# CTRL_MODULE_CORE_PAD register map
Vendor: Texas Instruments
Registers are 32-bit, access per field, reset 0x10F010F unless marked. A register's access mark holds for its fields unless they carry their own. Offsets are as the file gives them; [hi:lo] are bit positions; 'fields as' and 'values as' point back to an identical list.

## CTRL_MODULE_CORE_PAD (part 4 of 7)
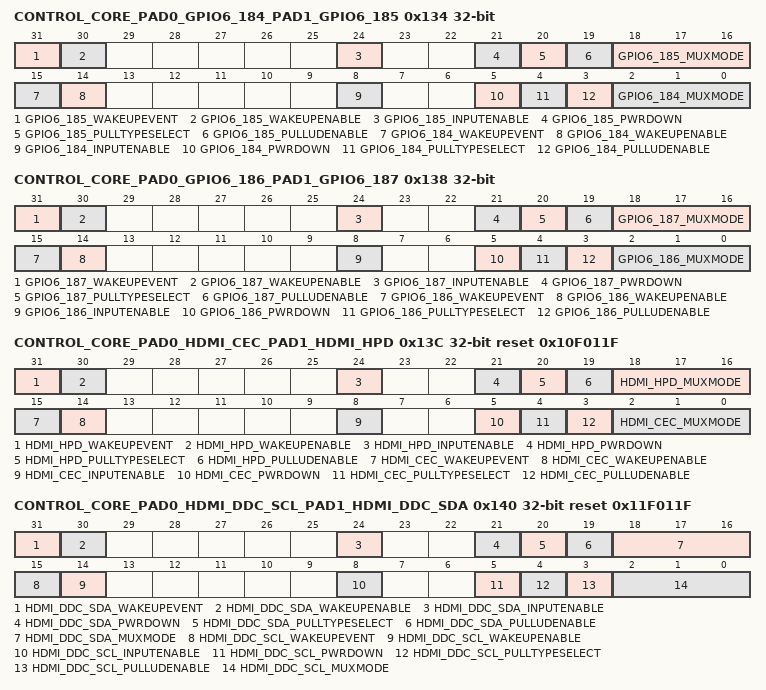
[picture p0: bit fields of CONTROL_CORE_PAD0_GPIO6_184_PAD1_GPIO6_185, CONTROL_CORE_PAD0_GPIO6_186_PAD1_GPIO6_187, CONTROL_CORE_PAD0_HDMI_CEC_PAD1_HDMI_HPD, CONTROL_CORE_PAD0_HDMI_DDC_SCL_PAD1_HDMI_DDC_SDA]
0x134 CONTROL_CORE_PAD0_GPIO6_184_PAD1_GPIO6_185 — Register control for Pads gpio6_184 and gpio6_185 Access conditions. Read: unrestricted, Write: unrestricted
  [31] GPIO6_185_WAKEUPEVENT ro — Pad_x wake-up event status latched in the IO
    1=WakeUp (A wake-up event occurred); 0=No wake-up event occurred
  [30] GPIO6_185_WAKEUPENABLE rw — Input pad wake-up enable
    0=DetectLow (wake-up detection is disabled); 1=DetectLowHigh (wake-up detection is enabled)
  [24] GPIO6_185_INPUTENABLE rw — Input enable value for pad gpio6_185
    0=InputBufferDisabled (Input buffer of IO cell is disabled); 1=InputBufferEnabled (Input buffer of IO cell is enabled)
  [21] GPIO6_185_PWRDOWN rw — Power Down setting for pad gpio6_185
    0=PwrDownDisabled (IO cell power is ON); 1=PwrDownEnabled (IO cell power is OFF)
  [20] GPIO6_185_PULLTYPESELECT rw — Pull-Up/Down selection for pad gpio6_185
    0=Pull-Down selected; 1=Pull-Up selected
  [19] GPIO6_185_PULLUDENABLE rw — Pull-Up/Down enable for pad gpio6_185
    0=PullDisabled (Pull-Up/Down disabled); 1=PullEnabled (Pull-Up/Down enabled)
  [18:16] GPIO6_185_MUXMODE rw — Functional multiplexing selection for pad gpio6_185
    6=SEL_GPIO6_185_1 (Select gpio6_185); 7=SEL_SAFE_MODE_CORE87 (Select safe_mode_core87); 0=SEL_GPIO6_185 (Select gpio6_185); 4=SEL_KBD_ROW0 (Select kbd_row0); 5=SEL_HW_DBG23 (Select hw_dbg23); 3=SEL_DISPC_DATA21 (Select dispc_data21)
  [15] GPIO6_184_WAKEUPEVENT ro — Pad_x wake-up event status latched in the IO
    values as GPIO6_185_WAKEUPEVENT
  [14] GPIO6_184_WAKEUPENABLE rw — Input pad wake-up enable
    values as GPIO6_185_WAKEUPENABLE
  [8] GPIO6_184_INPUTENABLE rw — Input enable value for pad gpio6_184
    values as GPIO6_185_INPUTENABLE
  [5] GPIO6_184_PWRDOWN rw — Power Down setting for pad gpio6_184
    values as GPIO6_185_PWRDOWN
  [4] GPIO6_184_PULLTYPESELECT rw — Pull-Up/Down selection for pad gpio6_184
    0=Pull-Down selected; 1=Pull-Up selected
  [3] GPIO6_184_PULLUDENABLE rw — Pull-Up/Down enable for pad gpio6_184
    values as GPIO6_185_PULLUDENABLE
  [2:0] GPIO6_184_MUXMODE rw — Functional multiplexing selection for pad gpio6_184
    6=SEL_GPIO6_184_1 (Select gpio6_184); 7=SEL_SAFE_MODE_CORE86 (Select safe_mode_core86); 0=SEL_GPIO6_184 (Select gpio6_184); 4=SEL_KBD_COL2 (Select kbd_col2); 5=SEL_HW_DBG22 (Select hw_dbg22); 3=SEL_DISPC_DATA20 (Select dispc_data20)
0x138 CONTROL_CORE_PAD0_GPIO6_186_PAD1_GPIO6_187 — Register control for Pads gpio6_186 and gpio6_187 Access conditions. Read: unrestricted, Write: unrestricted
  [31] GPIO6_187_WAKEUPEVENT ro — Pad_x wake-up event status latched in the IO
    values as CONTROL_CORE_PAD0_GPIO6_184_PAD1_GPIO6_185.GPIO6_185_WAKEUPEVENT
  [30] GPIO6_187_WAKEUPENABLE rw — Input pad wake-up enable
    values as CONTROL_CORE_PAD0_GPIO6_184_PAD1_GPIO6_185.GPIO6_185_WAKEUPENABLE
  [24] GPIO6_187_INPUTENABLE rw — Input enable value for pad gpio6_187
    values as CONTROL_CORE_PAD0_GPIO6_184_PAD1_GPIO6_185.GPIO6_185_INPUTENABLE
  [21] GPIO6_187_PWRDOWN rw — Power Down setting for pad gpio6_187
    values as CONTROL_CORE_PAD0_GPIO6_184_PAD1_GPIO6_185.GPIO6_185_PWRDOWN
  [20] GPIO6_187_PULLTYPESELECT rw — Pull-Up/Down selection for pad gpio6_187
    0=Pull-Down selected; 1=Pull-Up selected
  [19] GPIO6_187_PULLUDENABLE rw — Pull-Up/Down enable for pad gpio6_187
    values as CONTROL_CORE_PAD0_GPIO6_184_PAD1_GPIO6_185.GPIO6_185_PULLUDENABLE
  [18:16] GPIO6_187_MUXMODE rw — Functional multiplexing selection for pad gpio6_187
    6=SEL_GPIO6_187_1 (Select gpio6_187); 7=SEL_SAFE_MODE_CORE89 (Select safe_mode_core89); 0=SEL_GPIO6_187 (Select gpio6_187); 4=SEL_KBD_ROW2 (Select kbd_row2); 5=SEL_HW_DBG25 (Select hw_dbg25); 3=SEL_DISPC_DATA23 (Select dispc_data23)
  [15] GPIO6_186_WAKEUPEVENT ro — Pad_x wake-up event status latched in the IO
    values as CONTROL_CORE_PAD0_GPIO6_184_PAD1_GPIO6_185.GPIO6_185_WAKEUPEVENT
  [14] GPIO6_186_WAKEUPENABLE rw — Input pad wake-up enable
    values as CONTROL_CORE_PAD0_GPIO6_184_PAD1_GPIO6_185.GPIO6_185_WAKEUPENABLE
  [8] GPIO6_186_INPUTENABLE rw — Input enable value for pad gpio6_186
    values as CONTROL_CORE_PAD0_GPIO6_184_PAD1_GPIO6_185.GPIO6_185_INPUTENABLE
  [5] GPIO6_186_PWRDOWN rw — Power Down setting for pad gpio6_186
    values as CONTROL_CORE_PAD0_GPIO6_184_PAD1_GPIO6_185.GPIO6_185_PWRDOWN
  [4] GPIO6_186_PULLTYPESELECT rw — Pull-Up/Down selection for pad gpio6_186
    0=Pull-Down selected; 1=Pull-Up selected
  [3] GPIO6_186_PULLUDENABLE rw — Pull-Up/Down enable for pad gpio6_186
    values as CONTROL_CORE_PAD0_GPIO6_184_PAD1_GPIO6_185.GPIO6_185_PULLUDENABLE
  [2:0] GPIO6_186_MUXMODE rw — Functional multiplexing selection for pad gpio6_186
    6=SEL_GPIO6_186_1 (Select gpio6_186); 7=SEL_SAFE_MODE_CORE88 (Select safe_mode_core88); 0=SEL_GPIO6_186 (Select gpio6_186); 4=SEL_KBD_ROW1 (Select kbd_row1); 5=SEL_HW_DBG24 (Select hw_dbg24); 3=SEL_DISPC_DATA22 (Select dispc_data22)
0x13C CONTROL_CORE_PAD0_HDMI_CEC_PAD1_HDMI_HPD reset 0x10F011F — Register control for Pads hdmi_cec and hdmi_hpd Access conditions. Read: unrestricted, Write: unrestricted
  [31] HDMI_HPD_WAKEUPEVENT ro — Pad_x wake-up event status latched in the IO
    values as CONTROL_CORE_PAD0_GPIO6_184_PAD1_GPIO6_185.GPIO6_185_WAKEUPEVENT
  [30] HDMI_HPD_WAKEUPENABLE rw — Input pad wake-up enable
    values as CONTROL_CORE_PAD0_GPIO6_184_PAD1_GPIO6_185.GPIO6_185_WAKEUPENABLE
  [24] HDMI_HPD_INPUTENABLE rw — Input enable value for pad hdmi_hpd
    values as CONTROL_CORE_PAD0_GPIO6_184_PAD1_GPIO6_185.GPIO6_185_INPUTENABLE
  [21] HDMI_HPD_PWRDOWN rw — Power Down setting for pad hdmi_hpd
    values as CONTROL_CORE_PAD0_GPIO6_184_PAD1_GPIO6_185.GPIO6_185_PWRDOWN
  [20] HDMI_HPD_PULLTYPESELECT rw — Pull-Up/Down selection for pad hdmi_hpd
    0=Pull-Down selected; 1=Pull-Up selected
  [19] HDMI_HPD_PULLUDENABLE rw — Pull-Up/Down enable for pad hdmi_hpd
    values as CONTROL_CORE_PAD0_GPIO6_184_PAD1_GPIO6_185.GPIO6_185_PULLUDENABLE
  [18:16] HDMI_HPD_MUXMODE rw — Functional multiplexing selection for pad hdmi_hpd
    0=SEL_HDMI_HPD (Select hdmi_hpd); 7=SEL_SAFE_MODE_CORE107 (Select safe_mode_core107); 6=SEL_GPIO7_193 (Select gpio7_193)
  [15] HDMI_CEC_WAKEUPEVENT ro — Pad_x wake-up event status latched in the IO
    values as CONTROL_CORE_PAD0_GPIO6_184_PAD1_GPIO6_185.GPIO6_185_WAKEUPEVENT
  [14] HDMI_CEC_WAKEUPENABLE rw — Input pad wake-up enable
    values as CONTROL_CORE_PAD0_GPIO6_184_PAD1_GPIO6_185.GPIO6_185_WAKEUPENABLE
  [8] HDMI_CEC_INPUTENABLE rw — Input enable value for pad hdmi_cec
    values as CONTROL_CORE_PAD0_GPIO6_184_PAD1_GPIO6_185.GPIO6_185_INPUTENABLE
  [5] HDMI_CEC_PWRDOWN rw — Power Down setting for pad hdmi_cec
    values as CONTROL_CORE_PAD0_GPIO6_184_PAD1_GPIO6_185.GPIO6_185_PWRDOWN
  [4] HDMI_CEC_PULLTYPESELECT rw — Pull-Up/Down selection for pad hdmi_cec
    0=Pull-Down selected; 1=Pull-Up selected
  [3] HDMI_CEC_PULLUDENABLE rw — Pull-Up/Down enable for pad hdmi_cec
    values as CONTROL_CORE_PAD0_GPIO6_184_PAD1_GPIO6_185.GPIO6_185_PULLUDENABLE
  [2:0] HDMI_CEC_MUXMODE rw — Functional multiplexing selection for pad hdmi_cec
    0=SEL_HDMI_CEC (Select hdmi_cec); 7=SEL_SAFE_MODE_CORE106 (Select safe_mode_core106); 6=SEL_GPIO7_192 (Select gpio7_192)
0x140 CONTROL_CORE_PAD0_HDMI_DDC_SCL_PAD1_HDMI_DDC_SDA reset 0x11F011F — Register control for Pads hdmi_ddc_scl and hdmi_ddc_sda Access conditions. Read: unrestricted, Write: unrestricted
  [31] HDMI_DDC_SDA_WAKEUPEVENT ro — Pad_x wake-up event status latched in the IO
    values as CONTROL_CORE_PAD0_GPIO6_184_PAD1_GPIO6_185.GPIO6_185_WAKEUPEVENT
  [30] HDMI_DDC_SDA_WAKEUPENABLE rw — Input pad wake-up enable
    values as CONTROL_CORE_PAD0_GPIO6_184_PAD1_GPIO6_185.GPIO6_185_WAKEUPENABLE
  [24] HDMI_DDC_SDA_INPUTENABLE rw — Input enable value for pad hdmi_ddc_sda
    values as CONTROL_CORE_PAD0_GPIO6_184_PAD1_GPIO6_185.GPIO6_185_INPUTENABLE
  [21] HDMI_DDC_SDA_PWRDOWN rw — Power Down setting for pad hdmi_ddc_sda
    values as CONTROL_CORE_PAD0_GPIO6_184_PAD1_GPIO6_185.GPIO6_185_PWRDOWN
  [20] HDMI_DDC_SDA_PULLTYPESELECT rw — Pull-Up/Down selection for pad hdmi_ddc_sda
    0=Pull-Down selected; 1=Pull-Up selected
  [19] HDMI_DDC_SDA_PULLUDENABLE rw — Pull-Up/Down enable for pad hdmi_ddc_sda
    values as CONTROL_CORE_PAD0_GPIO6_184_PAD1_GPIO6_185.GPIO6_185_PULLUDENABLE
  [18:16] HDMI_DDC_SDA_MUXMODE rw — Functional multiplexing selection for pad hdmi_ddc_sda
    0=SEL_HDMI_DDC_SDA (Select hdmi_ddc_sda); 7=SEL_SAFE_MODE_CORE109 (Select safe_mode_core109); 6=SEL_GPIO7_195 (Select gpio7_195)
  [15] HDMI_DDC_SCL_WAKEUPEVENT ro — Pad_x wake-up event status latched in the IO
    values as CONTROL_CORE_PAD0_GPIO6_184_PAD1_GPIO6_185.GPIO6_185_WAKEUPEVENT
  [14] HDMI_DDC_SCL_WAKEUPENABLE rw — Input pad wake-up enable
    values as CONTROL_CORE_PAD0_GPIO6_184_PAD1_GPIO6_185.GPIO6_185_WAKEUPENABLE
  [8] HDMI_DDC_SCL_INPUTENABLE rw — Input enable value for pad hdmi_ddc_scl
    values as CONTROL_CORE_PAD0_GPIO6_184_PAD1_GPIO6_185.GPIO6_185_INPUTENABLE
  [5] HDMI_DDC_SCL_PWRDOWN rw — Power Down setting for pad hdmi_ddc_scl
    values as CONTROL_CORE_PAD0_GPIO6_184_PAD1_GPIO6_185.GPIO6_185_PWRDOWN
  [4] HDMI_DDC_SCL_PULLTYPESELECT rw — Pull-Up/Down selection for pad hdmi_ddc_scl
    0=Pull-Down selected; 1=Pull-Up selected
  [3] HDMI_DDC_SCL_PULLUDENABLE rw — Pull-Up/Down enable for pad hdmi_ddc_scl
    values as CONTROL_CORE_PAD0_GPIO6_184_PAD1_GPIO6_185.GPIO6_185_PULLUDENABLE
  [2:0] HDMI_DDC_SCL_MUXMODE rw — Functional multiplexing selection for pad hdmi_ddc_scl
    0=SEL_HDMI_DDC_SCL (Select hdmi_ddc_scl); 7=SEL_SAFE_MODE_CORE108 (Select safe_mode_core108); 6=SEL_GPIO7_194 (Select gpio7_194)
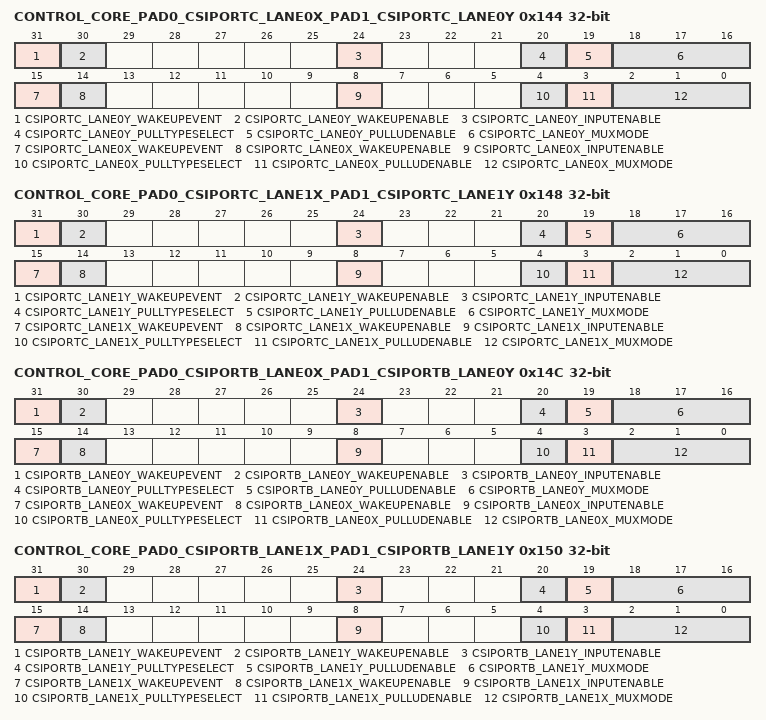
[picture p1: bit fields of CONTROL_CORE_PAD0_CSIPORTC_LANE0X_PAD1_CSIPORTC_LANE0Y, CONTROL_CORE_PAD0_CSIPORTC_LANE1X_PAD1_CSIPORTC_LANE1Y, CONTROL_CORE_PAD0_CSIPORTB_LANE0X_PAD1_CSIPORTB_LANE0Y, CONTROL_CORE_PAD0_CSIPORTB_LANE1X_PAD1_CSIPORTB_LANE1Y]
0x144 CONTROL_CORE_PAD0_CSIPORTC_LANE0X_PAD1_CSIPORTC_LANE0Y — Register control for Pads csiportc_lane0x and csiportc_lane0y Access conditions. Read: unrestricted, Write: unrestricted
  [31] CSIPORTC_LANE0Y_WAKEUPEVENT ro — Pad_x wake-up event status latched in the IO
    values as CONTROL_CORE_PAD0_GPIO6_184_PAD1_GPIO6_185.GPIO6_185_WAKEUPEVENT
  [30] CSIPORTC_LANE0Y_WAKEUPENABLE rw — Input pad wake-up enable
    values as CONTROL_CORE_PAD0_GPIO6_184_PAD1_GPIO6_185.GPIO6_185_WAKEUPENABLE
  [24] CSIPORTC_LANE0Y_INPUTENABLE rw — Input enable value for pad csiportc_lane0y
    values as CONTROL_CORE_PAD0_GPIO6_184_PAD1_GPIO6_185.GPIO6_185_INPUTENABLE
  [20] CSIPORTC_LANE0Y_PULLTYPESELECT rw — Pull-Up/Down selection for pad csiportc_lane0y
    0=Pull-Down selected; 1=Pull-Up selected
  [19] CSIPORTC_LANE0Y_PULLUDENABLE rw — Pull-Up/Down enable for pad csiportc_lane0y
    values as CONTROL_CORE_PAD0_GPIO6_184_PAD1_GPIO6_185.GPIO6_185_PULLUDENABLE
  [18:16] CSIPORTC_LANE0Y_MUXMODE rw — Functional multiplexing selection for pad csiportc_lane0y
    0=SEL_CSIPORTC_LANE0Y (Select csiportc_lane0y); 3=SEL_CPI_DATA8 (Select cpi_data8); 7=SEL_SAFE_MODE_CORE126 (Select safe_mode_core126); 6=SEL_GPIO8_IN252 (Select gpio8_in252)
  [15] CSIPORTC_LANE0X_WAKEUPEVENT ro — Pad_x wake-up event status latched in the IO
    values as CONTROL_CORE_PAD0_GPIO6_184_PAD1_GPIO6_185.GPIO6_185_WAKEUPEVENT
  [14] CSIPORTC_LANE0X_WAKEUPENABLE rw — Input pad wake-up enable
    values as CONTROL_CORE_PAD0_GPIO6_184_PAD1_GPIO6_185.GPIO6_185_WAKEUPENABLE
  [8] CSIPORTC_LANE0X_INPUTENABLE rw — Input enable value for pad csiportc_lane0x
    values as CONTROL_CORE_PAD0_GPIO6_184_PAD1_GPIO6_185.GPIO6_185_INPUTENABLE
  [4] CSIPORTC_LANE0X_PULLTYPESELECT rw — Pull-Up/Down selection for pad csiportc_lane0x
    0=Pull-Down selected; 1=Pull-Up selected
  [3] CSIPORTC_LANE0X_PULLUDENABLE rw — Pull-Up/Down enable for pad csiportc_lane0x
    values as CONTROL_CORE_PAD0_GPIO6_184_PAD1_GPIO6_185.GPIO6_185_PULLUDENABLE
  [2:0] CSIPORTC_LANE0X_MUXMODE rw — Functional multiplexing selection for pad csiportc_lane0x
    0=SEL_CSIPORTC_LANE0X (Select csiportc_lane0x); 3=SEL_CPI_DATA9 (Select cpi_data9); 7=SEL_SAFE_MODE_CORE127 (Select safe_mode_core127); 6=SEL_GPIO8_IN253 (Select gpio8_in253)
0x148 CONTROL_CORE_PAD0_CSIPORTC_LANE1X_PAD1_CSIPORTC_LANE1Y — Register control for Pads csiportc_lane1x and csiportc_lane1y Access conditions. Read: unrestricted, Write: unrestricted
  [31] CSIPORTC_LANE1Y_WAKEUPEVENT ro — Pad_x wake-up event status latched in the IO
    values as CONTROL_CORE_PAD0_GPIO6_184_PAD1_GPIO6_185.GPIO6_185_WAKEUPEVENT
  [30] CSIPORTC_LANE1Y_WAKEUPENABLE rw — Input pad wake-up enable
    values as CONTROL_CORE_PAD0_GPIO6_184_PAD1_GPIO6_185.GPIO6_185_WAKEUPENABLE
  [24] CSIPORTC_LANE1Y_INPUTENABLE rw — Input enable value for pad csiportc_lane1y
    values as CONTROL_CORE_PAD0_GPIO6_184_PAD1_GPIO6_185.GPIO6_185_INPUTENABLE
  [20] CSIPORTC_LANE1Y_PULLTYPESELECT rw — Pull-Up/Down selection for pad csiportc_lane1y
    0=Pull-Down selected; 1=Pull-Up selected
  [19] CSIPORTC_LANE1Y_PULLUDENABLE rw — Pull-Up/Down enable for pad csiportc_lane1y
    values as CONTROL_CORE_PAD0_GPIO6_184_PAD1_GPIO6_185.GPIO6_185_PULLUDENABLE
  [18:16] CSIPORTC_LANE1Y_MUXMODE rw — Functional multiplexing selection for pad csiportc_lane1y
    0=SEL_CSIPORTC_LANE1Y (Select csiportc_lane1y); 3=SEL_CPI_DATA10 (Select cpi_data10); 7=SEL_SAFE_MODE_CORE128 (Select safe_mode_core128); 6=SEL_GPIO8_IN254 (Select gpio8_in254)
  [15] CSIPORTC_LANE1X_WAKEUPEVENT ro — Pad_x wake-up event status latched in the IO
    values as CONTROL_CORE_PAD0_GPIO6_184_PAD1_GPIO6_185.GPIO6_185_WAKEUPEVENT
  [14] CSIPORTC_LANE1X_WAKEUPENABLE rw — Input pad wake-up enable
    values as CONTROL_CORE_PAD0_GPIO6_184_PAD1_GPIO6_185.GPIO6_185_WAKEUPENABLE
  [8] CSIPORTC_LANE1X_INPUTENABLE rw — Input enable value for pad csiportc_lane1x
    values as CONTROL_CORE_PAD0_GPIO6_184_PAD1_GPIO6_185.GPIO6_185_INPUTENABLE
  [4] CSIPORTC_LANE1X_PULLTYPESELECT rw — Pull-Up/Down selection for pad csiportc_lane1x
    0=Pull-Down selected; 1=Pull-Up selected
  [3] CSIPORTC_LANE1X_PULLUDENABLE rw — Pull-Up/Down enable for pad csiportc_lane1x
    values as CONTROL_CORE_PAD0_GPIO6_184_PAD1_GPIO6_185.GPIO6_185_PULLUDENABLE
  [2:0] CSIPORTC_LANE1X_MUXMODE rw — Functional multiplexing selection for pad csiportc_lane1x
    0=SEL_CSIPORTC_LANE1X (Select csiportc_lane1x); 3=SEL_CPI_DATA11 (Select cpi_data11); 7=SEL_SAFE_MODE_CORE129 (Select safe_mode_core129); 6=SEL_GPIO8_IN255 (Select gpio8_in255)
0x14C CONTROL_CORE_PAD0_CSIPORTB_LANE0X_PAD1_CSIPORTB_LANE0Y — Register control for Pads csiportb_lane0x and csiportb_lane0y Access conditions. Read: unrestricted, Write: unrestricted
  [31] CSIPORTB_LANE0Y_WAKEUPEVENT ro — Pad_x wake-up event status latched in the IO
    values as CONTROL_CORE_PAD0_GPIO6_184_PAD1_GPIO6_185.GPIO6_185_WAKEUPEVENT
  [30] CSIPORTB_LANE0Y_WAKEUPENABLE rw — Input pad wake-up enable
    values as CONTROL_CORE_PAD0_GPIO6_184_PAD1_GPIO6_185.GPIO6_185_WAKEUPENABLE
  [24] CSIPORTB_LANE0Y_INPUTENABLE rw — Input enable value for pad csiportb_lane0y
    values as CONTROL_CORE_PAD0_GPIO6_184_PAD1_GPIO6_185.GPIO6_185_INPUTENABLE
  [20] CSIPORTB_LANE0Y_PULLTYPESELECT rw — Pull-Up/Down selection for pad csiportb_lane0y
    0=Pull-Down selected; 1=Pull-Up selected
  [19] CSIPORTB_LANE0Y_PULLUDENABLE rw — Pull-Up/Down enable for pad csiportb_lane0y
    values as CONTROL_CORE_PAD0_GPIO6_184_PAD1_GPIO6_185.GPIO6_185_PULLUDENABLE
  [18:16] CSIPORTB_LANE0Y_MUXMODE rw — Functional multiplexing selection for pad csiportb_lane0y
    0=SEL_CSIPORTB_LANE0Y (Select csiportb_lane0y); 4=SEL_CPI_DATA13 (Select cpi_data13); 7=SEL_SAFE_MODE_CORE121 (Select safe_mode_core121); 6=SEL_GPIO8_IN247 (Select gpio8_in247)
  [15] CSIPORTB_LANE0X_WAKEUPEVENT ro — Pad_x wake-up event status latched in the IO
    values as CONTROL_CORE_PAD0_GPIO6_184_PAD1_GPIO6_185.GPIO6_185_WAKEUPEVENT
  [14] CSIPORTB_LANE0X_WAKEUPENABLE rw — Input pad wake-up enable
    values as CONTROL_CORE_PAD0_GPIO6_184_PAD1_GPIO6_185.GPIO6_185_WAKEUPENABLE
  [8] CSIPORTB_LANE0X_INPUTENABLE rw — Input enable value for pad csiportb_lane0x
    values as CONTROL_CORE_PAD0_GPIO6_184_PAD1_GPIO6_185.GPIO6_185_INPUTENABLE
  [4] CSIPORTB_LANE0X_PULLTYPESELECT rw — Pull-Up/Down selection for pad csiportb_lane0x
    0=Pull-Down selected; 1=Pull-Up selected
  [3] CSIPORTB_LANE0X_PULLUDENABLE rw — Pull-Up/Down enable for pad csiportb_lane0x
    values as CONTROL_CORE_PAD0_GPIO6_184_PAD1_GPIO6_185.GPIO6_185_PULLUDENABLE
  [2:0] CSIPORTB_LANE0X_MUXMODE rw — Functional multiplexing selection for pad csiportb_lane0x
    0=SEL_CSIPORTB_LANE0X (Select csiportb_lane0x); 4=SEL_CPI_DATA12 (Select cpi_data12); 7=SEL_SAFE_MODE_CORE120 (Select safe_mode_core120); 6=SEL_GPIO8_IN246 (Select gpio8_in246)
0x150 CONTROL_CORE_PAD0_CSIPORTB_LANE1X_PAD1_CSIPORTB_LANE1Y — Register control for Pads csiportb_lane1x and csiportb_lane1y Access conditions. Read: unrestricted, Write: unrestricted
  [31] CSIPORTB_LANE1Y_WAKEUPEVENT ro — Pad_x wake-up event status latched in the IO
    values as CONTROL_CORE_PAD0_GPIO6_184_PAD1_GPIO6_185.GPIO6_185_WAKEUPEVENT
  [30] CSIPORTB_LANE1Y_WAKEUPENABLE rw — Input pad wake-up enable
    values as CONTROL_CORE_PAD0_GPIO6_184_PAD1_GPIO6_185.GPIO6_185_WAKEUPENABLE
  [24] CSIPORTB_LANE1Y_INPUTENABLE rw — Input enable value for pad csiportb_lane1y
    values as CONTROL_CORE_PAD0_GPIO6_184_PAD1_GPIO6_185.GPIO6_185_INPUTENABLE
  [20] CSIPORTB_LANE1Y_PULLTYPESELECT rw — Pull-Up/Down selection for pad csiportb_lane1y
    0=Pull-Down selected; 1=Pull-Up selected
  [19] CSIPORTB_LANE1Y_PULLUDENABLE rw — Pull-Up/Down enable for pad csiportb_lane1y
    values as CONTROL_CORE_PAD0_GPIO6_184_PAD1_GPIO6_185.GPIO6_185_PULLUDENABLE
  [18:16] CSIPORTB_LANE1Y_MUXMODE rw — Functional multiplexing selection for pad csiportb_lane1y
    0=SEL_CSIPORTB_LANE1Y (Select csiportb_lane1y); 4=SEL_CPI_DATA14 (Select cpi_data14); 7=SEL_SAFE_MODE_CORE122 (Select safe_mode_core122); 6=SEL_GPIO8_IN248 (Select gpio8_in248)
  [15] CSIPORTB_LANE1X_WAKEUPEVENT ro — Pad_x wake-up event status latched in the IO
    values as CONTROL_CORE_PAD0_GPIO6_184_PAD1_GPIO6_185.GPIO6_185_WAKEUPEVENT
  [14] CSIPORTB_LANE1X_WAKEUPENABLE rw — Input pad wake-up enable
    values as CONTROL_CORE_PAD0_GPIO6_184_PAD1_GPIO6_185.GPIO6_185_WAKEUPENABLE
  [8] CSIPORTB_LANE1X_INPUTENABLE rw — Input enable value for pad csiportb_lane1x
    values as CONTROL_CORE_PAD0_GPIO6_184_PAD1_GPIO6_185.GPIO6_185_INPUTENABLE
  [4] CSIPORTB_LANE1X_PULLTYPESELECT rw — Pull-Up/Down selection for pad csiportb_lane1x
    0=Pull-Down selected; 1=Pull-Up selected
  [3] CSIPORTB_LANE1X_PULLUDENABLE rw — Pull-Up/Down enable for pad csiportb_lane1x
    values as CONTROL_CORE_PAD0_GPIO6_184_PAD1_GPIO6_185.GPIO6_185_PULLUDENABLE
  [2:0] CSIPORTB_LANE1X_MUXMODE rw — Functional multiplexing selection for pad csiportb_lane1x
    0=SEL_CSIPORTB_LANE1X (Select csiportb_lane1x); 4=SEL_CPI_DATA15 (Select cpi_data15); 7=SEL_SAFE_MODE_CORE123 (Select safe_mode_core123); 6=SEL_GPIO8_IN249 (Select gpio8_in249)
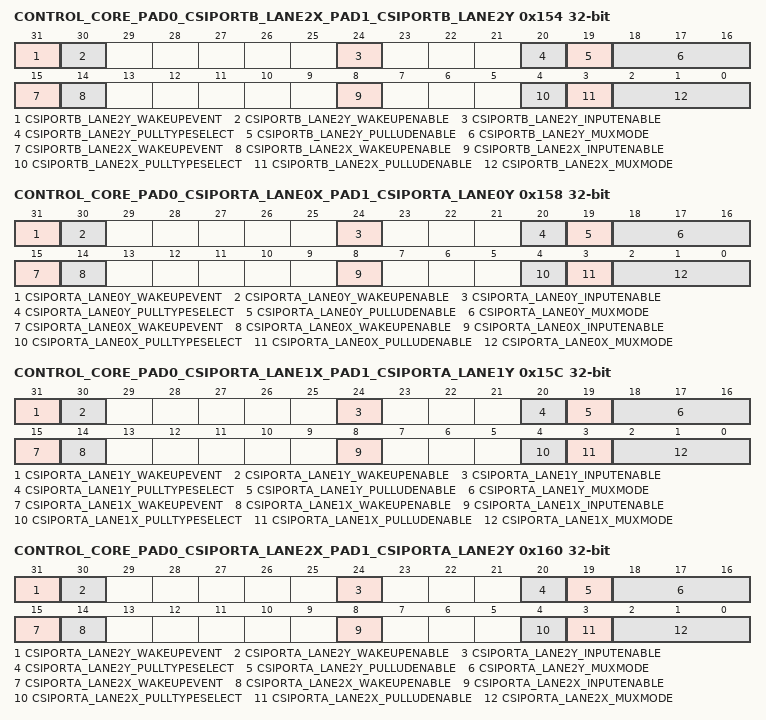
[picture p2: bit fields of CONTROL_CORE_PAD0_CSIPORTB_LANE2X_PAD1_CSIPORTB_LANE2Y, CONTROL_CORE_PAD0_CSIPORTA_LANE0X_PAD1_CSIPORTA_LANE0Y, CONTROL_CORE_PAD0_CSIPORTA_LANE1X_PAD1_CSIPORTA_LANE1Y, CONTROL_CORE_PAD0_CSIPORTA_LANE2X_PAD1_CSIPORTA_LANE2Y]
0x154 CONTROL_CORE_PAD0_CSIPORTB_LANE2X_PAD1_CSIPORTB_LANE2Y — Register control for Pads csiportb_lane2x and csiportb_lane2y Access conditions. Read: unrestricted, Write: unrestricted
  [31] CSIPORTB_LANE2Y_WAKEUPEVENT ro — Pad_x wake-up event status latched in the IO
    values as CONTROL_CORE_PAD0_GPIO6_184_PAD1_GPIO6_185.GPIO6_185_WAKEUPEVENT
  [30] CSIPORTB_LANE2Y_WAKEUPENABLE rw — Input pad wake-up enable
    values as CONTROL_CORE_PAD0_GPIO6_184_PAD1_GPIO6_185.GPIO6_185_WAKEUPENABLE
  [24] CSIPORTB_LANE2Y_INPUTENABLE rw — Input enable value for pad csiportb_lane2y
    values as CONTROL_CORE_PAD0_GPIO6_184_PAD1_GPIO6_185.GPIO6_185_INPUTENABLE
  [20] CSIPORTB_LANE2Y_PULLTYPESELECT rw — Pull-Up/Down selection for pad csiportb_lane2y
    0=Pull-Down selected; 1=Pull-Up selected
  [19] CSIPORTB_LANE2Y_PULLUDENABLE rw — Pull-Up/Down enable for pad csiportb_lane2y
    values as CONTROL_CORE_PAD0_GPIO6_184_PAD1_GPIO6_185.GPIO6_185_PULLUDENABLE
  [18:16] CSIPORTB_LANE2Y_MUXMODE rw — Functional multiplexing selection for pad csiportb_lane2y
    0=SEL_CSIPORTB_LANE2Y (Select csiportb_lane2y); 4=SEL_CPI_HSYNCIN (Select cpi_hsyncin); 7=SEL_SAFE_MODE_CORE124 (Select safe_mode_core124); 6=SEL_GPIO8_IN250 (Select gpio8_in250)
  [15] CSIPORTB_LANE2X_WAKEUPEVENT ro — Pad_x wake-up event status latched in the IO
    values as CONTROL_CORE_PAD0_GPIO6_184_PAD1_GPIO6_185.GPIO6_185_WAKEUPEVENT
  [14] CSIPORTB_LANE2X_WAKEUPENABLE rw — Input pad wake-up enable
    values as CONTROL_CORE_PAD0_GPIO6_184_PAD1_GPIO6_185.GPIO6_185_WAKEUPENABLE
  [8] CSIPORTB_LANE2X_INPUTENABLE rw — Input enable value for pad csiportb_lane2x
    values as CONTROL_CORE_PAD0_GPIO6_184_PAD1_GPIO6_185.GPIO6_185_INPUTENABLE
  [4] CSIPORTB_LANE2X_PULLTYPESELECT rw — Pull-Up/Down selection for pad csiportb_lane2x
    0=Pull-Down selected; 1=Pull-Up selected
  [3] CSIPORTB_LANE2X_PULLUDENABLE rw — Pull-Up/Down enable for pad csiportb_lane2x
    values as CONTROL_CORE_PAD0_GPIO6_184_PAD1_GPIO6_185.GPIO6_185_PULLUDENABLE
  [2:0] CSIPORTB_LANE2X_MUXMODE rw — Functional multiplexing selection for pad csiportb_lane2x
    0=SEL_CSIPORTB_LANE2X (Select csiportb_lane2x); 4=SEL_CPI_VSYNCIN (Select cpi_vsyncin); 7=SEL_SAFE_MODE_CORE125 (Select safe_mode_core125); 6=SEL_GPIO8_IN251 (Select gpio8_in251)
0x158 CONTROL_CORE_PAD0_CSIPORTA_LANE0X_PAD1_CSIPORTA_LANE0Y — Register control for Pads csiporta_lane0x and csiporta_lane0y Access conditions. Read: unrestricted, Write: unrestricted
  [31] CSIPORTA_LANE0Y_WAKEUPEVENT ro — Pad_x wake-up event status latched in the IO
    values as CONTROL_CORE_PAD0_GPIO6_184_PAD1_GPIO6_185.GPIO6_185_WAKEUPEVENT
  [30] CSIPORTA_LANE0Y_WAKEUPENABLE rw — Input pad wake-up enable
    values as CONTROL_CORE_PAD0_GPIO6_184_PAD1_GPIO6_185.GPIO6_185_WAKEUPENABLE
  [24] CSIPORTA_LANE0Y_INPUTENABLE rw — Input enable value for pad csiporta_lane0y
    values as CONTROL_CORE_PAD0_GPIO6_184_PAD1_GPIO6_185.GPIO6_185_INPUTENABLE
  [20] CSIPORTA_LANE0Y_PULLTYPESELECT rw — Pull-Up/Down selection for pad csiporta_lane0y
    0=Pull-Down selected; 1=Pull-Up selected
  [19] CSIPORTA_LANE0Y_PULLUDENABLE rw — Pull-Up/Down enable for pad csiporta_lane0y
    values as CONTROL_CORE_PAD0_GPIO6_184_PAD1_GPIO6_185.GPIO6_185_PULLUDENABLE
  [18:16] CSIPORTA_LANE0Y_MUXMODE rw — Functional multiplexing selection for pad csiporta_lane0y
    0=SEL_CSIPORTA_LANE0Y (Select csiporta_lane0y); 3=SEL_CPI_WEN (Select cpi_wen); 7=SEL_SAFE_MODE_CORE111 (Select safe_mode_core111); 6=SEL_GPIO8_IN237 (Select gpio8_in237)
  [15] CSIPORTA_LANE0X_WAKEUPEVENT ro — Pad_x wake-up event status latched in the IO
    values as CONTROL_CORE_PAD0_GPIO6_184_PAD1_GPIO6_185.GPIO6_185_WAKEUPEVENT
  [14] CSIPORTA_LANE0X_WAKEUPENABLE rw — Input pad wake-up enable
    values as CONTROL_CORE_PAD0_GPIO6_184_PAD1_GPIO6_185.GPIO6_185_WAKEUPENABLE
  [8] CSIPORTA_LANE0X_INPUTENABLE rw — Input enable value for pad csiporta_lane0x
    values as CONTROL_CORE_PAD0_GPIO6_184_PAD1_GPIO6_185.GPIO6_185_INPUTENABLE
  [4] CSIPORTA_LANE0X_PULLTYPESELECT rw — Pull-Up/Down selection for pad csiporta_lane0x
    0=Pull-Down selected; 1=Pull-Up selected
  [3] CSIPORTA_LANE0X_PULLUDENABLE rw — Pull-Up/Down enable for pad csiporta_lane0x
    values as CONTROL_CORE_PAD0_GPIO6_184_PAD1_GPIO6_185.GPIO6_185_PULLUDENABLE
  [2:0] CSIPORTA_LANE0X_MUXMODE rw — Functional multiplexing selection for pad csiporta_lane0x
    0=SEL_CSIPORTA_LANE0X (Select csiporta_lane0x); 3=SEL_CPI_PCLK (Select cpi_pclk); 7=SEL_SAFE_MODE_CORE110 (Select safe_mode_core110); 6=SEL_GPIO8_IN236 (Select gpio8_in236)
0x15C CONTROL_CORE_PAD0_CSIPORTA_LANE1X_PAD1_CSIPORTA_LANE1Y — Register control for Pads csiporta_lane1x and csiporta_lane1y Access conditions. Read: unrestricted, Write: unrestricted
  [31] CSIPORTA_LANE1Y_WAKEUPEVENT ro — Pad_x wake-up event status latched in the IO
    values as CONTROL_CORE_PAD0_GPIO6_184_PAD1_GPIO6_185.GPIO6_185_WAKEUPEVENT
  [30] CSIPORTA_LANE1Y_WAKEUPENABLE rw — Input pad wake-up enable
    values as CONTROL_CORE_PAD0_GPIO6_184_PAD1_GPIO6_185.GPIO6_185_WAKEUPENABLE
  [24] CSIPORTA_LANE1Y_INPUTENABLE rw — Input enable value for pad csiporta_lane1y
    values as CONTROL_CORE_PAD0_GPIO6_184_PAD1_GPIO6_185.GPIO6_185_INPUTENABLE
  [20] CSIPORTA_LANE1Y_PULLTYPESELECT rw — Pull-Up/Down selection for pad csiporta_lane1y
    0=Pull-Down selected; 1=Pull-Up selected
  [19] CSIPORTA_LANE1Y_PULLUDENABLE rw — Pull-Up/Down enable for pad csiporta_lane1y
    values as CONTROL_CORE_PAD0_GPIO6_184_PAD1_GPIO6_185.GPIO6_185_PULLUDENABLE
  [18:16] CSIPORTA_LANE1Y_MUXMODE rw — Functional multiplexing selection for pad csiporta_lane1y
    0=SEL_CSIPORTA_LANE1Y (Select csiporta_lane1y); 3=SEL_CPI_DATA0 (Select cpi_data0); 7=SEL_SAFE_MODE_CORE112 (Select safe_mode_core112); 6=SEL_GPIO8_IN238 (Select gpio8_in238)
  [15] CSIPORTA_LANE1X_WAKEUPEVENT ro — Pad_x wake-up event status latched in the IO
    values as CONTROL_CORE_PAD0_GPIO6_184_PAD1_GPIO6_185.GPIO6_185_WAKEUPEVENT
  [14] CSIPORTA_LANE1X_WAKEUPENABLE rw — Input pad wake-up enable
    values as CONTROL_CORE_PAD0_GPIO6_184_PAD1_GPIO6_185.GPIO6_185_WAKEUPENABLE
  [8] CSIPORTA_LANE1X_INPUTENABLE rw — Input enable value for pad csiporta_lane1x
    values as CONTROL_CORE_PAD0_GPIO6_184_PAD1_GPIO6_185.GPIO6_185_INPUTENABLE
  [4] CSIPORTA_LANE1X_PULLTYPESELECT rw — Pull-Up/Down selection for pad csiporta_lane1x
    0=Pull-Down selected; 1=Pull-Up selected
  [3] CSIPORTA_LANE1X_PULLUDENABLE rw — Pull-Up/Down enable for pad csiporta_lane1x
    values as CONTROL_CORE_PAD0_GPIO6_184_PAD1_GPIO6_185.GPIO6_185_PULLUDENABLE
  [2:0] CSIPORTA_LANE1X_MUXMODE rw — Functional multiplexing selection for pad csiporta_lane1x
    0=SEL_CSIPORTA_LANE1X (Select csiporta_lane1x); 3=SEL_CPI_DATA1 (Select cpi_data1); 7=SEL_SAFE_MODE_CORE113 (Select safe_mode_core113); 6=SEL_GPIO8_IN239 (Select gpio8_in239)
0x160 CONTROL_CORE_PAD0_CSIPORTA_LANE2X_PAD1_CSIPORTA_LANE2Y — Register control for Pads csiporta_lane2x and csiporta_lane2y Access conditions. Read: unrestricted, Write: unrestricted
  [31] CSIPORTA_LANE2Y_WAKEUPEVENT ro — Pad_x wake-up event status latched in the IO
    values as CONTROL_CORE_PAD0_GPIO6_184_PAD1_GPIO6_185.GPIO6_185_WAKEUPEVENT
  [30] CSIPORTA_LANE2Y_WAKEUPENABLE rw — Input pad wake-up enable
    values as CONTROL_CORE_PAD0_GPIO6_184_PAD1_GPIO6_185.GPIO6_185_WAKEUPENABLE
  [24] CSIPORTA_LANE2Y_INPUTENABLE rw — Input enable value for pad csiporta_lane2y
    values as CONTROL_CORE_PAD0_GPIO6_184_PAD1_GPIO6_185.GPIO6_185_INPUTENABLE
  [20] CSIPORTA_LANE2Y_PULLTYPESELECT rw — Pull-Up/Down selection for pad csiporta_lane2y
    0=Pull-Down selected; 1=Pull-Up selected
  [19] CSIPORTA_LANE2Y_PULLUDENABLE rw — Pull-Up/Down enable for pad csiporta_lane2y
    values as CONTROL_CORE_PAD0_GPIO6_184_PAD1_GPIO6_185.GPIO6_185_PULLUDENABLE
  [18:16] CSIPORTA_LANE2Y_MUXMODE rw — Functional multiplexing selection for pad csiporta_lane2y
    0=SEL_CSIPORTA_LANE2Y (Select csiporta_lane2y); 3=SEL_CPI_DATA2 (Select cpi_data2); 7=SEL_SAFE_MODE_CORE114 (Select safe_mode_core114); 6=SEL_GPIO8_IN240 (Select gpio8_in240)
  [15] CSIPORTA_LANE2X_WAKEUPEVENT ro — Pad_x wake-up event status latched in the IO
    values as CONTROL_CORE_PAD0_GPIO6_184_PAD1_GPIO6_185.GPIO6_185_WAKEUPEVENT
  [14] CSIPORTA_LANE2X_WAKEUPENABLE rw — Input pad wake-up enable
    values as CONTROL_CORE_PAD0_GPIO6_184_PAD1_GPIO6_185.GPIO6_185_WAKEUPENABLE
  [8] CSIPORTA_LANE2X_INPUTENABLE rw — Input enable value for pad csiporta_lane2x
    values as CONTROL_CORE_PAD0_GPIO6_184_PAD1_GPIO6_185.GPIO6_185_INPUTENABLE
  [4] CSIPORTA_LANE2X_PULLTYPESELECT rw — Pull-Up/Down selection for pad csiporta_lane2x
    0=Pull-Down selected; 1=Pull-Up selected
  [3] CSIPORTA_LANE2X_PULLUDENABLE rw — Pull-Up/Down enable for pad csiporta_lane2x
    values as CONTROL_CORE_PAD0_GPIO6_184_PAD1_GPIO6_185.GPIO6_185_PULLUDENABLE
  [2:0] CSIPORTA_LANE2X_MUXMODE rw — Functional multiplexing selection for pad csiporta_lane2x
    0=SEL_CSIPORTA_LANE2X (Select csiporta_lane2x); 3=SEL_CPI_DATA3 (Select cpi_data3); 7=SEL_SAFE_MODE_CORE115 (Select safe_mode_core115); 6=SEL_GPIO8_IN241 (Select gpio8_in241)
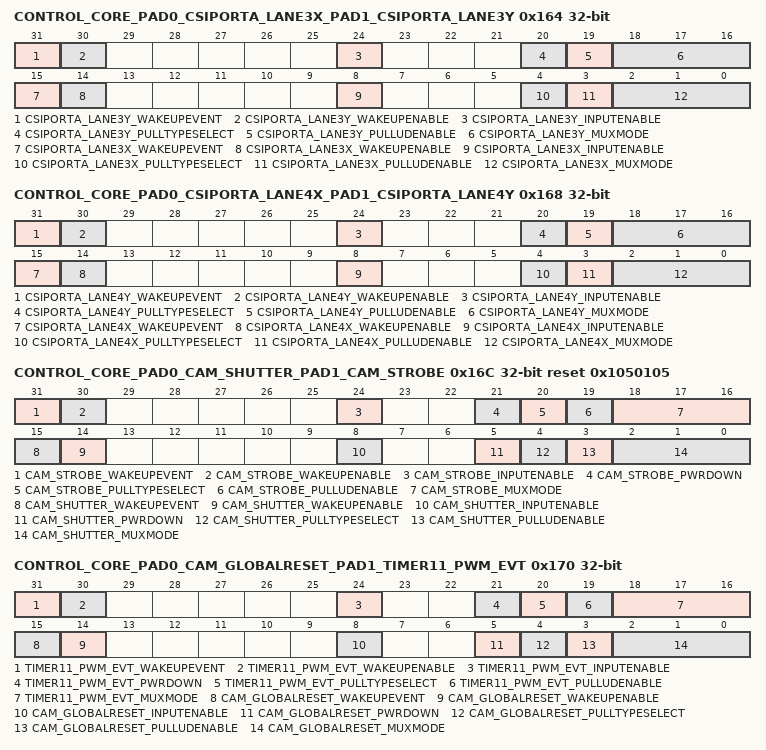
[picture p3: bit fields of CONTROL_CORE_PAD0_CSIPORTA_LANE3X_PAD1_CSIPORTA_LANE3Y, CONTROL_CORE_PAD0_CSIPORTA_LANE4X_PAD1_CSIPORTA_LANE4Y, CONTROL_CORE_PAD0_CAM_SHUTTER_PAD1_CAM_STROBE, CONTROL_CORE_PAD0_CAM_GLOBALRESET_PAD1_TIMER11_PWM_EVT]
0x164 CONTROL_CORE_PAD0_CSIPORTA_LANE3X_PAD1_CSIPORTA_LANE3Y — Register control for Pads csiporta_lane3x and csiporta_lane3y Access conditions. Read: unrestricted, Write: unrestricted
  [31] CSIPORTA_LANE3Y_WAKEUPEVENT ro — Pad_x wake-up event status latched in the IO
    values as CONTROL_CORE_PAD0_GPIO6_184_PAD1_GPIO6_185.GPIO6_185_WAKEUPEVENT
  [30] CSIPORTA_LANE3Y_WAKEUPENABLE rw — Input pad wake-up enable
    values as CONTROL_CORE_PAD0_GPIO6_184_PAD1_GPIO6_185.GPIO6_185_WAKEUPENABLE
  [24] CSIPORTA_LANE3Y_INPUTENABLE rw — Input enable value for pad csiporta_lane3y
    values as CONTROL_CORE_PAD0_GPIO6_184_PAD1_GPIO6_185.GPIO6_185_INPUTENABLE
  [20] CSIPORTA_LANE3Y_PULLTYPESELECT rw — Pull-Up/Down selection for pad csiporta_lane3y
    0=Pull-Down selected; 1=Pull-Up selected
  [19] CSIPORTA_LANE3Y_PULLUDENABLE rw — Pull-Up/Down enable for pad csiporta_lane3y
    values as CONTROL_CORE_PAD0_GPIO6_184_PAD1_GPIO6_185.GPIO6_185_PULLUDENABLE
  [18:16] CSIPORTA_LANE3Y_MUXMODE rw — Functional multiplexing selection for pad csiporta_lane3y
    0=SEL_CSIPORTA_LANE3Y (Select csiporta_lane3y); 3=SEL_CPI_DATA5 (Select cpi_data5); 7=SEL_SAFE_MODE_CORE117 (Select safe_mode_core117); 6=SEL_GPIO8_IN243 (Select gpio8_in243)
  [15] CSIPORTA_LANE3X_WAKEUPEVENT ro — Pad_x wake-up event status latched in the IO
    values as CONTROL_CORE_PAD0_GPIO6_184_PAD1_GPIO6_185.GPIO6_185_WAKEUPEVENT
  [14] CSIPORTA_LANE3X_WAKEUPENABLE rw — Input pad wake-up enable
    values as CONTROL_CORE_PAD0_GPIO6_184_PAD1_GPIO6_185.GPIO6_185_WAKEUPENABLE
  [8] CSIPORTA_LANE3X_INPUTENABLE rw — Input enable value for pad csiporta_lane3x
    values as CONTROL_CORE_PAD0_GPIO6_184_PAD1_GPIO6_185.GPIO6_185_INPUTENABLE
  [4] CSIPORTA_LANE3X_PULLTYPESELECT rw — Pull-Up/Down selection for pad csiporta_lane3x
    0=Pull-Down selected; 1=Pull-Up selected
  [3] CSIPORTA_LANE3X_PULLUDENABLE rw — Pull-Up/Down enable for pad csiporta_lane3x
    values as CONTROL_CORE_PAD0_GPIO6_184_PAD1_GPIO6_185.GPIO6_185_PULLUDENABLE
  [2:0] CSIPORTA_LANE3X_MUXMODE rw — Functional multiplexing selection for pad csiporta_lane3x
    0=SEL_CSIPORTA_LANE3X (Select csiporta_lane3x); 3=SEL_CPI_DATA4 (Select cpi_data4); 7=SEL_SAFE_MODE_CORE116 (Select safe_mode_core116); 6=SEL_GPIO8_IN242 (Select gpio8_in242)
0x168 CONTROL_CORE_PAD0_CSIPORTA_LANE4X_PAD1_CSIPORTA_LANE4Y — Register control for Pads csiporta_lane4x and csiporta_lane4y Access conditions. Read: unrestricted, Write: unrestricted
  [31] CSIPORTA_LANE4Y_WAKEUPEVENT ro — Pad_x wake-up event status latched in the IO
    values as CONTROL_CORE_PAD0_GPIO6_184_PAD1_GPIO6_185.GPIO6_185_WAKEUPEVENT
  [30] CSIPORTA_LANE4Y_WAKEUPENABLE rw — Input pad wake-up enable
    values as CONTROL_CORE_PAD0_GPIO6_184_PAD1_GPIO6_185.GPIO6_185_WAKEUPENABLE
  [24] CSIPORTA_LANE4Y_INPUTENABLE rw — Input enable value for pad csiporta_lane4y
    values as CONTROL_CORE_PAD0_GPIO6_184_PAD1_GPIO6_185.GPIO6_185_INPUTENABLE
  [20] CSIPORTA_LANE4Y_PULLTYPESELECT rw — Pull-Up/Down selection for pad csiporta_lane4y
    0=Pull-Down selected; 1=Pull-Up selected
  [19] CSIPORTA_LANE4Y_PULLUDENABLE rw — Pull-Up/Down enable for pad csiporta_lane4y
    values as CONTROL_CORE_PAD0_GPIO6_184_PAD1_GPIO6_185.GPIO6_185_PULLUDENABLE
  [18:16] CSIPORTA_LANE4Y_MUXMODE rw — Functional multiplexing selection for pad csiporta_lane4y
    0=SEL_CSIPORTA_LANE4Y (Select csiporta_lane4y); 3=SEL_CPI_DATA7 (Select cpi_data7); 7=SEL_SAFE_MODE_CORE119 (Select safe_mode_core119); 6=SEL_GPIO8_IN245 (Select gpio8_in245)
  [15] CSIPORTA_LANE4X_WAKEUPEVENT ro — Pad_x wake-up event status latched in the IO
    values as CONTROL_CORE_PAD0_GPIO6_184_PAD1_GPIO6_185.GPIO6_185_WAKEUPEVENT
  [14] CSIPORTA_LANE4X_WAKEUPENABLE rw — Input pad wake-up enable
    values as CONTROL_CORE_PAD0_GPIO6_184_PAD1_GPIO6_185.GPIO6_185_WAKEUPENABLE
  [8] CSIPORTA_LANE4X_INPUTENABLE rw — Input enable value for pad csiporta_lane4x
    values as CONTROL_CORE_PAD0_GPIO6_184_PAD1_GPIO6_185.GPIO6_185_INPUTENABLE
  [4] CSIPORTA_LANE4X_PULLTYPESELECT rw — Pull-Up/Down selection for pad csiporta_lane4x
    0=Pull-Down selected; 1=Pull-Up selected
  [3] CSIPORTA_LANE4X_PULLUDENABLE rw — Pull-Up/Down enable for pad csiporta_lane4x
    values as CONTROL_CORE_PAD0_GPIO6_184_PAD1_GPIO6_185.GPIO6_185_PULLUDENABLE
  [2:0] CSIPORTA_LANE4X_MUXMODE rw — Functional multiplexing selection for pad csiporta_lane4x
    0=SEL_CSIPORTA_LANE4X (Select csiporta_lane4x); 3=SEL_CPI_DATA6 (Select cpi_data6); 7=SEL_SAFE_MODE_CORE118 (Select safe_mode_core118); 6=SEL_GPIO8_IN244 (Select gpio8_in244)
0x16C CONTROL_CORE_PAD0_CAM_SHUTTER_PAD1_CAM_STROBE reset 0x1050105 — Register control for Pads cam_shutter and cam_strobe Access conditions. Read: unrestricted, Write: unrestricted
  [31] CAM_STROBE_WAKEUPEVENT ro — Pad_x wake-up event status latched in the IO
    values as CONTROL_CORE_PAD0_GPIO6_184_PAD1_GPIO6_185.GPIO6_185_WAKEUPEVENT
  [30] CAM_STROBE_WAKEUPENABLE rw — Input pad wake-up enable
    values as CONTROL_CORE_PAD0_GPIO6_184_PAD1_GPIO6_185.GPIO6_185_WAKEUPENABLE
  [24] CAM_STROBE_INPUTENABLE rw — Input enable value for pad cam_strobe
    values as CONTROL_CORE_PAD0_GPIO6_184_PAD1_GPIO6_185.GPIO6_185_INPUTENABLE
  [21] CAM_STROBE_PWRDOWN rw — Power Down setting for pad cam_strobe
    values as CONTROL_CORE_PAD0_GPIO6_184_PAD1_GPIO6_185.GPIO6_185_PWRDOWN
  [20] CAM_STROBE_PULLTYPESELECT rw — Pull-Up/Down selection for pad cam_strobe
    0=Pull-Down selected; 1=Pull-Up selected
  [19] CAM_STROBE_PULLUDENABLE rw — Pull-Up/Down enable for pad cam_strobe
    values as CONTROL_CORE_PAD0_GPIO6_184_PAD1_GPIO6_185.GPIO6_185_PULLUDENABLE
  [18:16] CAM_STROBE_MUXMODE rw — Functional multiplexing selection for pad cam_strobe
    0=SEL_CAM_STROBE (Select cam_strobe); 6=SEL_GPIO8_225 (Select gpio8_225); 7=SEL_SAFE_MODE_CORE131 (Select safe_mode_core131); 5=SEL_SYS_NODEID1 (Select sys_nodeid1)
  [15] CAM_SHUTTER_WAKEUPEVENT ro — Pad_x wake-up event status latched in the IO
    values as CONTROL_CORE_PAD0_GPIO6_184_PAD1_GPIO6_185.GPIO6_185_WAKEUPEVENT
  [14] CAM_SHUTTER_WAKEUPENABLE rw — Input pad wake-up enable
    values as CONTROL_CORE_PAD0_GPIO6_184_PAD1_GPIO6_185.GPIO6_185_WAKEUPENABLE
  [8] CAM_SHUTTER_INPUTENABLE rw — Input enable value for pad cam_shutter
    values as CONTROL_CORE_PAD0_GPIO6_184_PAD1_GPIO6_185.GPIO6_185_INPUTENABLE
  [5] CAM_SHUTTER_PWRDOWN rw — Power Down setting for pad cam_shutter
    values as CONTROL_CORE_PAD0_GPIO6_184_PAD1_GPIO6_185.GPIO6_185_PWRDOWN
  [4] CAM_SHUTTER_PULLTYPESELECT rw — Pull-Up/Down selection for pad cam_shutter
    0=Pull-Down selected; 1=Pull-Up selected
  [3] CAM_SHUTTER_PULLUDENABLE rw — Pull-Up/Down enable for pad cam_shutter
    values as CONTROL_CORE_PAD0_GPIO6_184_PAD1_GPIO6_185.GPIO6_185_PULLUDENABLE
  [2:0] CAM_SHUTTER_MUXMODE rw — Functional multiplexing selection for pad cam_shutter
    0=SEL_CAM_SHUTTER (Select cam_shutter); 6=SEL_GPIO8_224 (Select gpio8_224); 7=SEL_SAFE_MODE_CORE130 (Select safe_mode_core130); 5=SEL_SYS_NODEID0 (Select sys_nodeid0)
0x170 CONTROL_CORE_PAD0_CAM_GLOBALRESET_PAD1_TIMER11_PWM_EVT — Register control for Pads cam_globalreset and timer11_pwm_evt Access conditions. Read: unrestricted, Write: unrestricted
  [31] TIMER11_PWM_EVT_WAKEUPEVENT ro — Pad_x wake-up event status latched in the IO
    values as CONTROL_CORE_PAD0_GPIO6_184_PAD1_GPIO6_185.GPIO6_185_WAKEUPEVENT
  [30] TIMER11_PWM_EVT_WAKEUPENABLE rw — Input pad wake-up enable
    values as CONTROL_CORE_PAD0_GPIO6_184_PAD1_GPIO6_185.GPIO6_185_WAKEUPENABLE
  [24] TIMER11_PWM_EVT_INPUTENABLE rw — Input enable value for pad timer11_pwm_evt
    values as CONTROL_CORE_PAD0_GPIO6_184_PAD1_GPIO6_185.GPIO6_185_INPUTENABLE
  [21] TIMER11_PWM_EVT_PWRDOWN rw — Power Down setting for pad timer11_pwm_evt
    values as CONTROL_CORE_PAD0_GPIO6_184_PAD1_GPIO6_185.GPIO6_185_PWRDOWN
  [20] TIMER11_PWM_EVT_PULLTYPESELECT rw — Pull-Up/Down selection for pad timer11_pwm_evt
    0=Pull-Down selected; 1=Pull-Up selected
  [19] TIMER11_PWM_EVT_PULLUDENABLE rw — Pull-Up/Down enable for pad timer11_pwm_evt
    values as CONTROL_CORE_PAD0_GPIO6_184_PAD1_GPIO6_185.GPIO6_185_PULLUDENABLE
  [18:16] TIMER11_PWM_EVT_MUXMODE rw — Functional multiplexing selection for pad timer11_pwm_evt
    0=SEL_TIMER11_PWM_EVT (Select timer11_pwm_evt); 2=SEL_UART1_TX (Select uart1_tx); 6=SEL_GPIO8_227 (Select gpio8_227); 3=SEL_CPI_DATA12 (Select cpi_data12); 7=SEL_SAFE_MODE_CORE133 (Select safe_mode_core133); 5=SEL_HW_DBG26 (Select hw_dbg26)
  [15] CAM_GLOBALRESET_WAKEUPEVENT ro — Pad_x wake-up event status latched in the IO
    values as CONTROL_CORE_PAD0_GPIO6_184_PAD1_GPIO6_185.GPIO6_185_WAKEUPEVENT
  [14] CAM_GLOBALRESET_WAKEUPENABLE rw — Input pad wake-up enable
    values as CONTROL_CORE_PAD0_GPIO6_184_PAD1_GPIO6_185.GPIO6_185_WAKEUPENABLE
  [8] CAM_GLOBALRESET_INPUTENABLE rw — Input enable value for pad cam_globalreset
    values as CONTROL_CORE_PAD0_GPIO6_184_PAD1_GPIO6_185.GPIO6_185_INPUTENABLE
  [5] CAM_GLOBALRESET_PWRDOWN rw — Power Down setting for pad cam_globalreset
    values as CONTROL_CORE_PAD0_GPIO6_184_PAD1_GPIO6_185.GPIO6_185_PWRDOWN
  [4] CAM_GLOBALRESET_PULLTYPESELECT rw — Pull-Up/Down selection for pad cam_globalreset
    0=Pull-Down selected; 1=Pull-Up selected
  [3] CAM_GLOBALRESET_PULLUDENABLE rw — Pull-Up/Down enable for pad cam_globalreset
    values as CONTROL_CORE_PAD0_GPIO6_184_PAD1_GPIO6_185.GPIO6_185_PULLUDENABLE
  [2:0] CAM_GLOBALRESET_MUXMODE rw — Functional multiplexing selection for pad cam_globalreset
    0=SEL_CAM_GLOBALRESET (Select cam_globalreset); 1=SEL_CAM_SHUTTER (Select cam_shutter); 3=SEL_CPI_FID (Select cpi_fid); 7=SEL_SAFE_MODE_CORE132 (Select safe_mode_core132); 6=SEL_GPIO8_226 (Select gpio8_226)
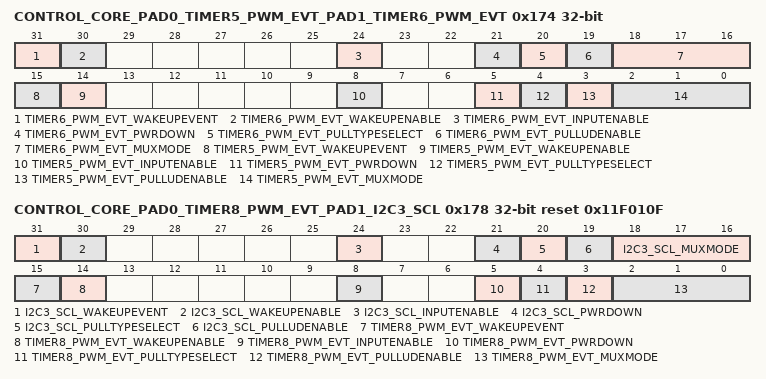
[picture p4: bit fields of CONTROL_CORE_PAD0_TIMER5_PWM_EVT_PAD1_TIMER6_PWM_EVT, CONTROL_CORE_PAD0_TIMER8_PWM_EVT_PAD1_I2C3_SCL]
0x174 CONTROL_CORE_PAD0_TIMER5_PWM_EVT_PAD1_TIMER6_PWM_EVT — Register control for Pads timer5_pwm_evt and timer6_pwm_evt Access conditions. Read: unrestricted, Write: unrestricted
  [31] TIMER6_PWM_EVT_WAKEUPEVENT ro — Pad_x wake-up event status latched in the IO
    values as CONTROL_CORE_PAD0_GPIO6_184_PAD1_GPIO6_185.GPIO6_185_WAKEUPEVENT
  [30] TIMER6_PWM_EVT_WAKEUPENABLE rw — Input pad wake-up enable
    values as CONTROL_CORE_PAD0_GPIO6_184_PAD1_GPIO6_185.GPIO6_185_WAKEUPENABLE
  [24] TIMER6_PWM_EVT_INPUTENABLE rw — Input enable value for pad timer6_pwm_evt
    values as CONTROL_CORE_PAD0_GPIO6_184_PAD1_GPIO6_185.GPIO6_185_INPUTENABLE
  [21] TIMER6_PWM_EVT_PWRDOWN rw — Power Down setting for pad timer6_pwm_evt
    values as CONTROL_CORE_PAD0_GPIO6_184_PAD1_GPIO6_185.GPIO6_185_PWRDOWN
  [20] TIMER6_PWM_EVT_PULLTYPESELECT rw — Pull-Up/Down selection for pad timer6_pwm_evt
    0=Pull-Down selected; 1=Pull-Up selected
  [19] TIMER6_PWM_EVT_PULLUDENABLE rw — Pull-Up/Down enable for pad timer6_pwm_evt
    values as CONTROL_CORE_PAD0_GPIO6_184_PAD1_GPIO6_185.GPIO6_185_PULLUDENABLE
  [18:16] TIMER6_PWM_EVT_MUXMODE rw — Functional multiplexing selection for pad timer6_pwm_evt
    0=SEL_TIMER6_PWM_EVT (Select timer6_pwm_evt); 1=SEL_SDCARD_WP (Select sdcard_wp); 2=SEL_UART1_RX (Select uart1_rx); 3=SEL_CPI_DATA14 (Select cpi_data14); 7=SEL_SAFE_MODE_CORE135 (Select safe_mode_core135); 6=SEL_GPIO8_229 (Select gpio8_229)
  [15] TIMER5_PWM_EVT_WAKEUPEVENT ro — Pad_x wake-up event status latched in the IO
    values as CONTROL_CORE_PAD0_GPIO6_184_PAD1_GPIO6_185.GPIO6_185_WAKEUPEVENT
  [14] TIMER5_PWM_EVT_WAKEUPENABLE rw — Input pad wake-up enable
    values as CONTROL_CORE_PAD0_GPIO6_184_PAD1_GPIO6_185.GPIO6_185_WAKEUPENABLE
  [8] TIMER5_PWM_EVT_INPUTENABLE rw — Input enable value for pad timer5_pwm_evt
    values as CONTROL_CORE_PAD0_GPIO6_184_PAD1_GPIO6_185.GPIO6_185_INPUTENABLE
  [5] TIMER5_PWM_EVT_PWRDOWN rw — Power Down setting for pad timer5_pwm_evt
    values as CONTROL_CORE_PAD0_GPIO6_184_PAD1_GPIO6_185.GPIO6_185_PWRDOWN
  [4] TIMER5_PWM_EVT_PULLTYPESELECT rw — Pull-Up/Down selection for pad timer5_pwm_evt
    0=Pull-Down selected; 1=Pull-Up selected
  [3] TIMER5_PWM_EVT_PULLUDENABLE rw — Pull-Up/Down enable for pad timer5_pwm_evt
    values as CONTROL_CORE_PAD0_GPIO6_184_PAD1_GPIO6_185.GPIO6_185_PULLUDENABLE
  [2:0] TIMER5_PWM_EVT_MUXMODE rw — Functional multiplexing selection for pad timer5_pwm_evt
    0=SEL_TIMER5_PWM_EVT (Select timer5_pwm_evt); 1=SEL_SDCARD_CD (Select sdcard_cd); 2=SEL_UART1_CTS (Select uart1_cts); 3=SEL_CPI_DATA13 (Select cpi_data13); 7=SEL_SAFE_MODE_CORE134 (Select safe_mode_core134); 6=SEL_GPIO8_228 (Select gpio8_228)
0x178 CONTROL_CORE_PAD0_TIMER8_PWM_EVT_PAD1_I2C3_SCL reset 0x11F010F — Register control for Pads timer8_pwm_evt and i2c3_scl Access conditions. Read: unrestricted, Write: unrestricted
  [31] I2C3_SCL_WAKEUPEVENT ro — Pad_x wake-up event status latched in the IO
    values as CONTROL_CORE_PAD0_GPIO6_184_PAD1_GPIO6_185.GPIO6_185_WAKEUPEVENT
  [30] I2C3_SCL_WAKEUPENABLE rw — Input pad wake-up enable
    values as CONTROL_CORE_PAD0_GPIO6_184_PAD1_GPIO6_185.GPIO6_185_WAKEUPENABLE
  [24] I2C3_SCL_INPUTENABLE rw — Input enable value for pad i2c3_scl
    values as CONTROL_CORE_PAD0_GPIO6_184_PAD1_GPIO6_185.GPIO6_185_INPUTENABLE
  [21] I2C3_SCL_PWRDOWN rw — Power Down setting for pad i2c3_scl
    values as CONTROL_CORE_PAD0_GPIO6_184_PAD1_GPIO6_185.GPIO6_185_PWRDOWN
  [20] I2C3_SCL_PULLTYPESELECT rw — Pull-Up/Down selection for pad i2c3_scl
    0=Pull-Down selected; 1=Pull-Up selected
  [19] I2C3_SCL_PULLUDENABLE rw — Pull-Up/Down enable for pad i2c3_scl
    values as CONTROL_CORE_PAD0_GPIO6_184_PAD1_GPIO6_185.GPIO6_185_PULLUDENABLE
  [18:16] I2C3_SCL_MUXMODE rw — Functional multiplexing selection for pad i2c3_scl
    0=SEL_I2C3_SCL (Select i2c3_scl); 7=SEL_SAFE_MODE_CORE137 (Select safe_mode_core137); 6=SEL_GPIO8_231 (Select gpio8_231)
  [15] TIMER8_PWM_EVT_WAKEUPEVENT ro — Pad_x wake-up event status latched in the IO
    values as CONTROL_CORE_PAD0_GPIO6_184_PAD1_GPIO6_185.GPIO6_185_WAKEUPEVENT
  [14] TIMER8_PWM_EVT_WAKEUPENABLE rw — Input pad wake-up enable
    values as CONTROL_CORE_PAD0_GPIO6_184_PAD1_GPIO6_185.GPIO6_185_WAKEUPENABLE
  [8] TIMER8_PWM_EVT_INPUTENABLE rw — Input enable value for pad timer8_pwm_evt
    values as CONTROL_CORE_PAD0_GPIO6_184_PAD1_GPIO6_185.GPIO6_185_INPUTENABLE
  [5] TIMER8_PWM_EVT_PWRDOWN rw — Power Down setting for pad timer8_pwm_evt
    values as CONTROL_CORE_PAD0_GPIO6_184_PAD1_GPIO6_185.GPIO6_185_PWRDOWN
  [4] TIMER8_PWM_EVT_PULLTYPESELECT rw — Pull-Up/Down selection for pad timer8_pwm_evt
    0=Pull-Down selected; 1=Pull-Up selected
  [3] TIMER8_PWM_EVT_PULLUDENABLE rw — Pull-Up/Down enable for pad timer8_pwm_evt
    values as CONTROL_CORE_PAD0_GPIO6_184_PAD1_GPIO6_185.GPIO6_185_PULLUDENABLE
  [2:0] TIMER8_PWM_EVT_MUXMODE rw — Functional multiplexing selection for pad timer8_pwm_evt
    0=SEL_TIMER8_PWM_EVT (Select timer8_pwm_evt); 1=SEL_SDCARD_WP (Select sdcard_wp); 2=SEL_UART1_RTS (Select uart1_rts); 6=SEL_GPIO8_230 (Select gpio8_230); 3=SEL_CPI_DATA15 (Select cpi_data15); 7=SEL_SAFE_MODE_CORE136 (Select safe_mode_core136); 5=SEL_HW_DBG27 (Select hw_dbg27)
